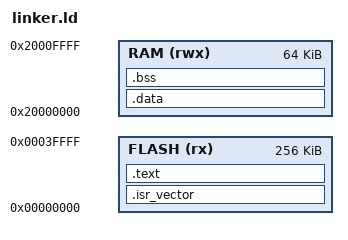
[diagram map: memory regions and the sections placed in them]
/* tracked */
ENTRY(Reset_Handler)

MEMORY
{
    FLASH (rx)  : ORIGIN = 0x00000000, LENGTH = 256K
    RAM   (rwx) : ORIGIN = 0x20000000, LENGTH = 64K
}

_estack = ORIGIN(RAM) + LENGTH(RAM);

SECTIONS
{
    /* Vector table must be first */
    .isr_vector :
    {
        KEEP(*(.isr_vector))
    } > FLASH

    .text :
    {
        *(.text*)
        *(.rodata*)
    } > FLASH

    /* Initialized data */
    .data : AT (ADDR(.text) + SIZEOF(.text))
    {
        _sdata = .;
        *(.data*)
        _edata = .;
    } > RAM

    /* Uninitialized data */
    .bss :
    {
        _sbss = .;
        *(.bss*)
        *(COMMON)
        _ebss = .;
    } > RAM
}

_sidata = LOADADDR(.data);
